# ATA5835 device description
Architecture: AVR8; Family: megaAVR
Registers are 8-bit, access not given, no defined reset value unless marked. A register's access mark holds for its fields unless they carry their own. Offsets are from the block's base; [hi:lo] are bit positions; {n}, {i} and the like mark numbered series.

## FUSE
Instances: FUSE 0 in fuses
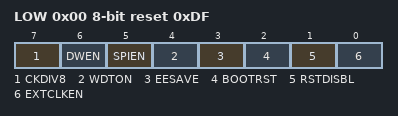
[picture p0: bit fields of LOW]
0x00 LOW reset 0xDF
  [7] CKDIV8 — Divide clock by 8 internally
  [6] DWEN — Debug Wire enable
  [5] SPIEN — Serial program downloading (SPI) enabled
  [4] WDTON — Watch-dog Timer always on
  [3] EESAVE — Preserve EEPROM memory through the Chip Erase cycle
  [2] BOOTRST — Select interrupt vector location
  [1] RSTDISBL — Disable external Reset
  [0] EXTCLKEN — External Clock enable

## LOCKBIT
Instances: LOCKBIT 0 in lockbits
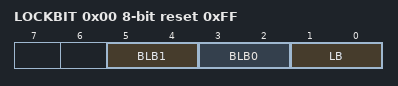
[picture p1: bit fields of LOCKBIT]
0x00 LOCKBIT reset 0xFF
  [5:4] BLB1 — Boot Loader Protection
    0=LPM_AND_SPM_PROHIBITED_IN_BOOT_LOADER_SECTION; 1=LPM_PROHIBITED_IN_BOOT_LOADER_SECTION; 2=SPM_PROHIBITED_IN_BOOT_LOADER_SECTION; 3=NO_LOCK_ON_SPM_AND_LPM_IN_BOOT_LOADER_SECTION
  [3:2] BLB0 — Application Protection
    0=LPM_AND_SPM_PROHIBITED_IN_APPLICATION_SECTION; 1=LPM_PROHIBITED_IN_APPLICATION_SECTION; 2=SPM_PROHIBITED_IN_APPLICATION_SECTION; 3=NO_LOCK_ON_SPM_AND_LPM_IN_APPLICATION_SECTION
  [1:0] LB — Memory Lock
    0=PROG_VER_DISABLED (Further programming and verification disabled); 2=PROG_DISABLED (Further programming disabled); 3=NO_LOCK (No memory lock features enabled)

## CALIB
Instances: CALIB 0x00
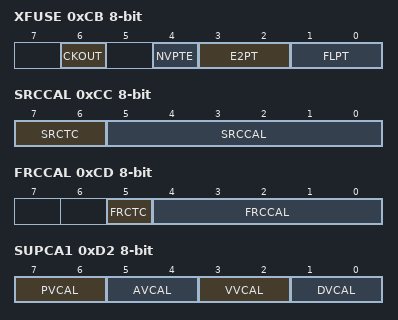
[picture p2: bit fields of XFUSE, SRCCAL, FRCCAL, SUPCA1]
0xCB XFUSE — XROW Fuse
  [6] CKOUT — CP2 Output on Port ckout
  [4] NVPTE — NVM Variable Programming Time Enable
  [3:2] E2PT — EEPROM Programming Time
  [1:0] FLPT — Flash Memory Programming Time
0xCC SRCCAL — Slow RC Oscillator Calibration
  [7:6] SRCTC — Slow RC Oscillator Temperature Compensation
  [5:0] SRCCAL — Slow RC Oscillator Calibration
0xCD FRCCAL — Fast RC Oscillator Calibration
  [5] FRCTC — Fast RC Oscillator Temperature Compensation
  [4:0] FRCCAL — Fast RC Oscillator Calibration
0xD2 SUPCA1 — Supply Calibration 1
  [7:6] PVCAL — PA Regulator Voltage Calibration
  [5:4] AVCAL — AVCC Regulator Voltage Calibration
  [3:2] VVCAL — VMEM Regulator Voltage Calibration
  [1:0] DVCAL — DVCC Regulator Voltage Calibration
0xD3 SUPCA2 — Supply Calibration 2
  [5:0] BGCAL — Band Gap Calibration
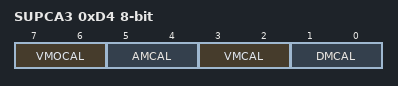
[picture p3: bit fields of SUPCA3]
0xD4 SUPCA3 — Supply Calibration 3
  [7:6] VMOCAL — Voltage Monitor Calibration
  [5:4] AMCAL — AVCC Monitor Calibration
  [3:2] VMCAL — VMEM Monitor Calibration
  [1:0] DMCAL — DVCC Monitor Calibration
0xD5 SUPCA4 — Supply Calibration 4
  [7:0] PTCAL — Bandgap PTAT Calibration
0xDA CALRDY — Calibration Ready Signature

## CHFLT
Instances: CHFLT 0x00
0xAF CHCR — Channel Filter Configuration Register
  [3:0] BWM — Bandwidth Mode
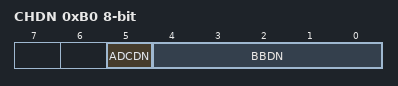
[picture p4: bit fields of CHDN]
0xB0 CHDN — Channel Filter Down Sampling Register
  [5] ADCDN — ADC Down Sampling Configuration
  [4:0] BBDN — Baseband Filter Down Sampling Ratio

## CLK
Instances: CLK 0x00
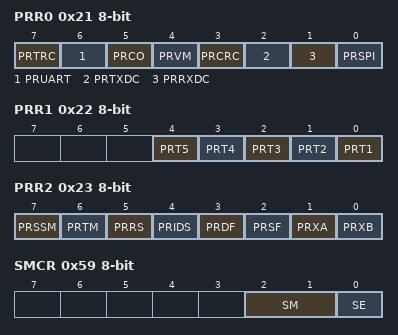
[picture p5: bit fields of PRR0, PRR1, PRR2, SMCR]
0x21 PRR0 — Power Reduction Register 0
  [7] PRTRC — Power Reduction Trace Unit
  [6] PRUART — Power Reduction UART
  [5] PRCO — Power Reduction Clock Output
  [4] PRVM — Power Reduction Voltage Monitor
  [3] PRCRC — Power Reduction CRC
  [2] PRTXDC — Power Reduction Transmit DSP Control
  [1] PRRXDC — Power Reduction Receive DSP Control
  [0] PRSPI — Power Reduction Serial Peripheral Interface
0x22 PRR1 — Power Reduction Register 1
  [n-1] PRT{n} (n=1..5) — Power Reduction Timer {n}
0x23 PRR2 — Power Reduction Register 2
  [7] PRSSM — Power Reduction Sequencer State Machine
  [6] PRTM — Power Reduction Tx Modulator
  [5] PRRS — Power Reduction RSSI Buffer
  [4] PRIDS — Power Reduction ID Check
  [3] PRDF — Power Reduction Data FIFO
  [2] PRSF — Power Reduction Support FIFO
  [1] PRXA — Power Reduction Rx Buffer A
  [0] PRXB — Power Reduction Rx Buffer B
0x59 SMCR — Sleep Mode Control Register
  [2:1] SM — Sleep Mode Select
    0=IDLE; 1=PDOWN (Power Down); 3=POFF (Power Off)
  [0] SE — Sleep Mode Enable
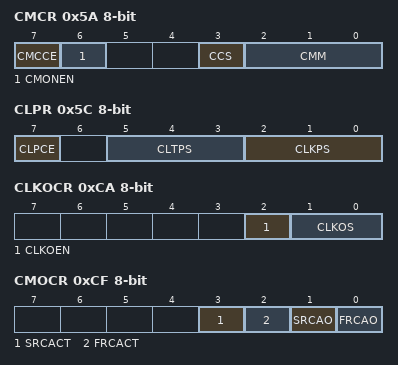
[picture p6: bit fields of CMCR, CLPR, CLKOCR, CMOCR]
0x5A CMCR — Clock Management Control Register
  [7] CMCCE — Clock Management Control Change Enable
  [6] CMONEN — Clock Monitor Enable
  [3] CCS — Core Clock Select
  [2:0] CMM — Clock Management Mode
    0=CLK_SRC; 1=CLK_ADIV; 2=CLK_EXT; 3=CLK_XTO6; 4=CLK_XTO4
0x5B CMIMR — Clock Management Interrupt Mask Register
  [0] ECIE — External Clock Interrupt Enable
0x5C CLPR — Clock Prescaler
  [7] CLPCE — Clock Prescaler Change Enable
  [5:3] CLTPS — Timer Clock Prescaler Select
    0=DISABLED; 1=1; 2=2; 3=4; 4=8; 5=16; 6=32; 7=64
  [2:0] CLKPS — System Clock Prescaler Select
    0=1; 1=2; 2=4; 3=8; 4=16; 5=32; 6=64; 7=128
0xC9 CLKOD — Clock Output Divider
0xCA CLKOCR — Clock output control Register
  [2] CLKOEN — Clock Output Driver Enable
  [1:0] CLKOS — Clock Output Source
    0=CLK_SRC; 1=CLK_FRC; 2=CLK_ADIV; 3=CLK_XTO
0xCE CMSR — Clock Management Status Register
  [0] ECF — External Clock Fail
0xCF CMOCR — Clock Management Override Control Register
  [3] SRCACT — SRC Oscillator Active
  [2] FRCACT — FRC Oscillator Active
  [1] SRCAO — SRC Oscillator Always On
  [0] FRCAO — FRC Oscillator Always On
